# DA14683 register map
Vendor: Dialog; Series: DA14683; File version: 1.2
CPU: CM0 r1p0, little endian, MPU, FPU, 3 interrupt priority bits
Registers are 16-bit, read-write, reset 0x0 unless marked. A register's access mark holds for its fields unless they carry their own. Offsets are from the block's base; [hi:lo] are bit positions.

## QUAD — QUAD registers
Base 0x50001A00
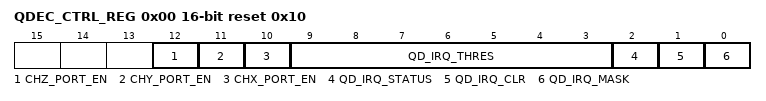
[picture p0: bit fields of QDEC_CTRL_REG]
0x00 QDEC_CTRL_REG reset 0x10 — Quad decoder control register
  [12] CHZ_PORT_EN — '1' : Enable channel
  [11] CHY_PORT_EN — '1' : Enable channel
  [10] CHX_PORT_EN — '1' : Enable channel
  [9:3] QD_IRQ_THRES — The number of events on either counter (X or Y or Z) that need to be reached before an interrupt is generated. If 0 is written, then threshold is considered to be 1.
  [2] QD_IRQ_STATUS ro — Interrupt Status. If 1 an interrupt has occured.
  [1] QD_IRQ_CLR — Writing 1 to this bit clears the interrupt. This bit is autocleared
  [0] QD_IRQ_MASK — 0: interrupt is masked 1: interrupt is enabled
0x02 QDEC_XCNT_REG — Counter value of the X Axis
  [15:0] X_counter ro — Contains a signed value of the events. Zero when channel is disabled
0x04 QDEC_YCNT_REG — Counter value of the Y Axis
  [15:0] Y_counter ro — Contains a signed value of the events. Zero when channel is disabled
0x06 QDEC_ZCNT_REG — Counter value of the Z Axis
  [15:0] Z_counter ro — Contains a signed value of the events. Zero when channel is disabled
0x08 QDEC_CLOCKDIV_REG — Quad decoder clock divider register
  [9:0] clock_divider — Contains the number of the input clock cycles minus one, that are required to generate one logic clock cycle.

## SPI — SPI registers
Base 0x50001200
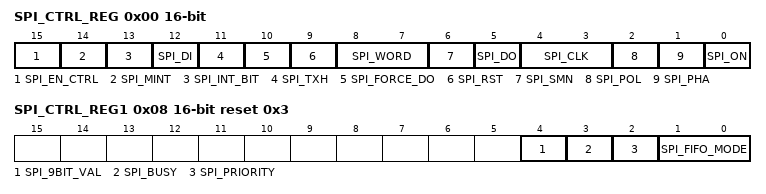
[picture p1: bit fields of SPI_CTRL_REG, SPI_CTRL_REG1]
0x00 SPI_CTRL_REG — SPI control register 0
  [15] SPI_EN_CTRL — 0 = SPI_EN pin disabled in slave mode. Pin SPI_EN is don't care. 1 = SPI_EN pin enabled in slave mode.
  [14] SPI_MINT — 0 = Disable SPI_INT_BIT to ICU 1 = Enable SPI_INT_BIT to ICU. Note that the SPI_INT interrupt is shared with AD_INT interrupt
  [13] SPI_INT_BIT ro — 0 = RX Register or FIFO is empty. 1 = SPI interrupt. Data has been transmitted and receivedMust be reset by SW by writing to SPI_CLEAR_INT_REG.
  [12] SPI_DI ro — Returns the actual value of pin SPI_DIN (delayed with two internal SPI clock cycles)
  [11] SPI_TXH ro — 0 = TX-FIFO is not full, data can be written. 1 = TX-FIFO is full, data can not be written.
  [10] SPI_FORCE_DO — 0 = normal operation 1 = Force SPIDO output level to value of SPI_DO.
  [9] SPI_RST — 0 = normal operation 1 = Reset SPI. Same function as SPI_ON except that internal clock remain active.
  [8:7] SPI_WORD — 00 = 8 bits mode, only SPI_RX_TX_REG0 used 01 = 16 bit mode, only SPI_RX_TX_REG0 used 10 = 32 bits mode, SPI_RX_TX_REG0 & SPI_RX_TX_REG1 used 11 = 9 bits mode. Only valid in master mode.
  [6] SPI_SMN — Master/slave mode 0 = Master, 1 = Slave(SPI1 only)
  [5] SPI_DO — Pin SPI_DO output level when SPI is idle or when SPI_FORCE_DO=1
  [4:3] SPI_CLK — Select SPI_CLK clock output frequency in master mode: 00 = SPI_CLK / 8 01 = SPI_CLK / 4 10 = SPI_CLK / 2 11 = SPI_CLK / 14
  [2] SPI_POL — Select SPI_CLK polarity. 0 = SPI_CLK is initially low. 1 = SPI_CLK is initially high.
  [1] SPI_PHA — Select SPI_CLK phase. See functional timing diagrams in SPI chapter
  [0] SPI_ON — 0 = SPI Module switched off (power saving). Everything is reset except SPI_CTRL_REG0 and SPI_CTRL_REG1. When this bit is cleared the SPI will remain active in master mode until the shift register and holding register are both empty. 1 = SPI Module switched on. Should only be set after all control bits have their desired values. So two writes are needed!
0x02 SPI_RX_TX_REG0 — SPI RX/TX register0
  [15:0] SPI_DATA0 wo — Write: SPI_TX_REG0 output register 0 (TX-FIFO) Read: SPI_RX_REG0 input register 0 (RX-FIFO) In 8 or 9 bits mode bits 15 to 8 are not used, they contain old data.
0x04 SPI_RX_TX_REG1 — SPI RX/TX register1
  [15:0] SPI_DATA1 wo — Write: SPI_TX_REG1 output register 1 (MSB's of TX-FIFO) Read: SPI_RX_REG1 input register 1 (MSB's of RX-FIFO) In 8 or 9 or 16 bits mode bits this register is not used.
0x06 SPI_CLEAR_INT_REG — SPI clear interrupt register
  [15:0] SPI_CLEAR_INT wo — Writing any value to this register will clear the SPI_CTRL_REG[SPI_INT_BIT] Reading returns 0.
0x08 SPI_CTRL_REG1 reset 0x3 — SPI control register 1
  [4] SPI_9BIT_VAL — Determines the value of the first bit in 9 bits SPI mode.
  [3] SPI_BUSY ro — 0 = The SPI is not busy with a transfer. This means that either no TX-data is available or that the transfers have been suspended due to a full RX-FIFO. The SPIx_CTRL_REG0[SPI_INT_BIT] can be used to distinguish between these situations. 1 = The SPI is busy with a transfer.
  [2] SPI_PRIORITY — 0 = The SPI has low priority, the DMA request signals are reset after the corresponding acknowledge. 1 = The SPI has high priority, DMA request signals remain active until the FIFOS are filled/emptied, so the DMA holds the AHB bus.
  [1:0] SPI_FIFO_MODE — 0: TX-FIFO and RX-FIFO used (Bidirectional mode). 1: RX-FIFO used (Read Only Mode) TX-FIFO single depth, no flow control 2: TX-FIFO used (Write Only Mode), RX-FIFO single depth, no flow control 3: No FIFOs used (backwards compatible mode)
